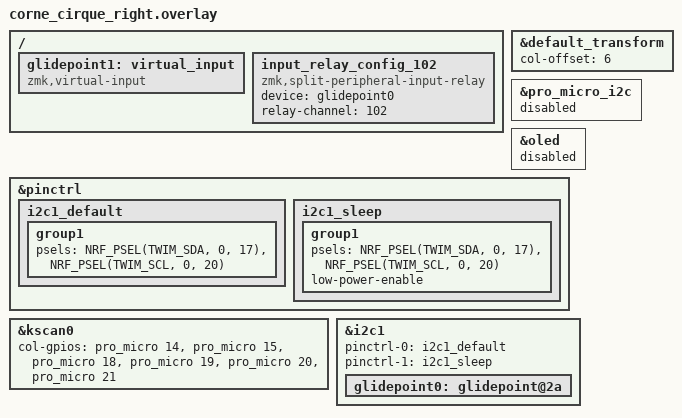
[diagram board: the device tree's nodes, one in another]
/*
 * Copyright (c) 2020 The ZMK Contributors
 *
 * SPDX-License-Identifier: MIT
 */

#include "corne_cirque.dtsi"

&default_transform {
    col-offset = <6>;
};

/* Disable OLED on right side */
&pro_micro_i2c {
    status = "disabled";
};

&oled {
    status = "disabled";
};

&pinctrl {
    i2c1_default: i2c1_default {
        group1 {
            psels = <NRF_PSEL(TWIM_SDA, 0, 17)>,
                    <NRF_PSEL(TWIM_SCL, 0, 20)>;
        };
    };

    i2c1_sleep: i2c1_sleep {
        group1 {
            psels = <NRF_PSEL(TWIM_SDA, 0, 17)>,
                    <NRF_PSEL(TWIM_SCL, 0, 20)>;
            low-power-enable;
        };
    };
};

&kscan0 {
    col-gpios
        = <&pro_micro 14 GPIO_ACTIVE_HIGH>
        , <&pro_micro 15 GPIO_ACTIVE_HIGH>
        , <&pro_micro 18 GPIO_ACTIVE_HIGH>
        , <&pro_micro 19 GPIO_ACTIVE_HIGH>
        , <&pro_micro 20 GPIO_ACTIVE_HIGH>
        , <&pro_micro 21 GPIO_ACTIVE_HIGH>
        ;
};

&i2c1 {
    status = "okay";
    pinctrl-0 = <&i2c1_default>;
    pinctrl-1 = <&i2c1_sleep>;
    pinctrl-names = "default", "sleep";

    glidepoint0: glidepoint@2a {
        status = "okay";
    };
};

/ {
    /* THIS only makes keymap binding happy, nothing happens on peripheral side */
    glidepoint1: virtual_input {
        compatible = "zmk,virtual-input";
    };

    input_relay_config_102 {
        compatible = "zmk,split-peripheral-input-relay";

        /* peripheral side input device, used to... */
        /*  - be intercepted on peripheral; */
        /*  - and then, be resurrected as `zmk,virtual-device` on central; */
        device = <&glidepoint0>;

        /* channel id, used to be transferred along with all input events. */
        /* NOTE 1: pick any 8bit integer. (1 - 255) */
        /* NOTE 2: should matching relay-channel on central overlay */
        relay-channel = <102>;
    };
};
